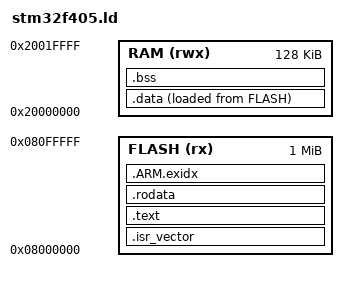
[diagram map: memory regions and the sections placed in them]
/* STM32F405 (Cortex-M4F): 1 MB flash, 128 KB contiguous SRAM (SRAM1 + SRAM2). QEMU: -M netduinoplus2. */
MEMORY
{
    FLASH (rx)  : ORIGIN = 0x08000000, LENGTH = 1024K
    RAM   (rwx) : ORIGIN = 0x20000000, LENGTH = 128K
}

ENTRY(reset_handler)

SECTIONS
{
    .isr_vector : { KEEP(*(.isr_vector)) } > FLASH
    .text : { *(.text*) . = ALIGN(4); } > FLASH
    .rodata : { *(.rodata*) . = ALIGN(4); } > FLASH
    .ARM.exidx : { *(.ARM.exidx*) } > FLASH
    _sidata = LOADADDR(.data);
    .data : { _sdata = .; *(.data*) . = ALIGN(4); _edata = .; } > RAM AT > FLASH
    .bss (NOLOAD) : { _sbss = .; *(.bss*) *(COMMON) . = ALIGN(4); _ebss = .; } > RAM
    _estack = ORIGIN(RAM) + LENGTH(RAM);
}
